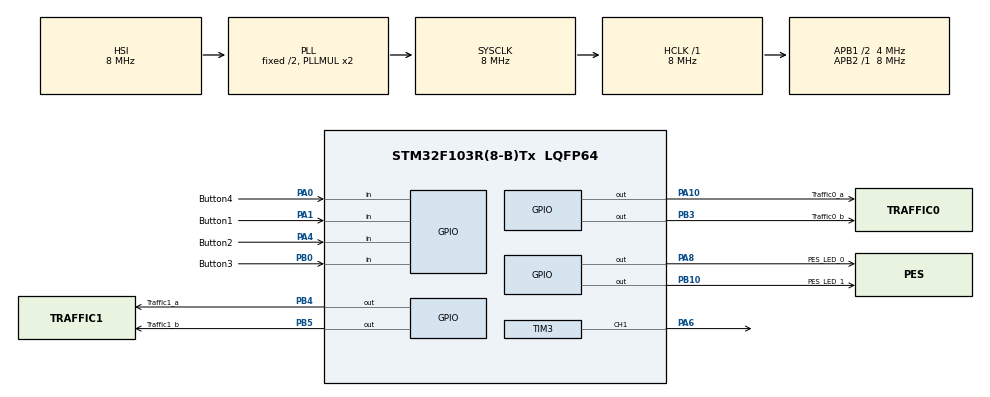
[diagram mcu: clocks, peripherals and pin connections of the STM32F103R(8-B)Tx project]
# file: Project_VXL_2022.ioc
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Mcu.Family=STM32F1
Mcu.Name=STM32F103R(8-B)Tx
Mcu.Package=LQFP64
NVIC.PriorityGroup=NVIC_PRIORITYGROUP_4
NVIC.TIM2_IRQn=true\:0\:0\:false\:false\:true\:true\:true
NVIC.TIM3_IRQn=true\:0\:0\:false\:false\:true\:true\:true
PA0-WKUP.GPIO_Label=Button4
PA0-WKUP.GPIO_PuPd=GPIO_PULLUP
PA0-WKUP.Signal=GPIO_Input
PA1.GPIO_Label=Button1
PA1.GPIO_PuPd=GPIO_PULLUP
PA1.Signal=GPIO_Input
PA10.GPIO_Label=Traffic0_a
PA10.Signal=GPIO_Output
PA13.Mode=Serial_Wire
PA13.Signal=SYS_JTMS-SWDIO
PA14.Mode=Serial_Wire
PA14.Signal=SYS_JTCK-SWCLK
PA4.GPIO_Label=Button2
PA4.GPIO_PuPd=GPIO_PULLUP
PA4.Signal=GPIO_Input
PA6.Signal=S_TIM3_CH1
PA8.GPIO_Label=PES_LED_0
PA8.Signal=GPIO_Output
PB0.GPIO_Label=Button3
PB0.GPIO_PuPd=GPIO_PULLUP
PB0.Signal=GPIO_Input
PB10.GPIO_Label=PES_LED_1
PB10.Signal=GPIO_Output
PB3.GPIO_Label=Traffic0_b
PB3.Signal=GPIO_Output
PB4.GPIO_Label=Traffic1_a
PB4.Signal=GPIO_Output
PB5.GPIO_Label=Traffic1_b
PB5.Signal=GPIO_Output
ProjectManager.HeapSize=0x200
ProjectManager.StackSize=0x400
ProjectManager.TargetToolchain=STM32CubeIDE
RCC.AHBFreq_Value=8000000
RCC.APB1CLKDivider=RCC_HCLK_DIV2
RCC.APB1Freq_Value=4000000
RCC.APB1TimFreq_Value=8000000
RCC.APB2Freq_Value=8000000
RCC.APB2TimFreq_Value=8000000
RCC.HCLKFreq_Value=8000000
RCC.SYSCLKFreq_VALUE=8000000
RCC.SYSCLKSource=RCC_SYSCLKSOURCE_PLLCLK
RCC.USBFreq_Value=8000000
SH.S_TIM3_CH1.0=TIM3_CH1,PWM Generation1 CH1
TIM2.Period=9
TIM2.Prescaler=7999
TIM3.Channel-PWM\ Generation1\ CH1=TIM_CHANNEL_1
TIM3.Period=999
TIM3.Prescaler=63
VP_TIM2_VS_ClockSourceINT.Mode=Internal
VP_TIM3_VS_ClockSourceINT.Mode=Internal
board=custom

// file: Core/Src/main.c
/* USER CODE BEGIN Header */
/**
  ******************************************************************************
  * @file           : main.c
  * @brief          : Main program body
  ******************************************************************************
  * @attention
  *
  * <h2><center>&copy; Copyright (c) 2022 STMicroelectronics.
  * All rights reserved.</center></h2>
  *
  * This software component is licensed by ST under BSD 3-Clause license,
  * the "License"; You may not use this file except in compliance with the
  * License. You may obtain a copy of the License at:
  *                        opensource.org/licenses/BSD-3-Clause
  *
  ******************************************************************************
  */
/* USER CODE END Header */
#include "main.h"
#include "tim.h"
#include "gpio.h"

/* USER CODE BEGIN Includes */
#include "global.h"
/* USER CODE END Includes */

void SystemClock_Config(void);

int main(void)
{

  /* MCU Configuration--------------------------------------------------------*/

  /* Reset of all peripherals, Initializes the Flash interface and the Systick. */
  HAL_Init();

  /* Configure the system clock */
  SystemClock_Config();

  /* Initialize all configured peripherals */
  MX_GPIO_Init();
  MX_TIM2_Init();
  MX_TIM3_Init();
  /* USER CODE BEGIN 2 */
  HAL_TIM_Base_Start_IT(&htim2);
  HAL_TIM_PWM_Start(&htim3, TIM_CHANNEL_1);
  /* USER CODE END 2 */

  /* Infinite loop */
  while (1)
  {

  }
}

void SystemClock_Config(void)
{
  RCC_OscInitTypeDef RCC_OscInitStruct = {0};
  RCC_ClkInitTypeDef RCC_ClkInitStruct = {0};

  /** Initializes the RCC Oscillators according to the specified parameters
  * in the RCC_OscInitTypeDef structure.
  */
  RCC_OscInitStruct.OscillatorType = RCC_OSCILLATORTYPE_HSI;
  RCC_OscInitStruct.HSIState = RCC_HSI_ON;
  RCC_OscInitStruct.HSICalibrationValue = RCC_HSICALIBRATION_DEFAULT;
  RCC_OscInitStruct.PLL.PLLState = RCC_PLL_ON;
  RCC_OscInitStruct.PLL.PLLSource = RCC_PLLSOURCE_HSI_DIV2;
  RCC_OscInitStruct.PLL.PLLMUL = RCC_PLL_MUL2;
  if (HAL_RCC_OscConfig(&RCC_OscInitStruct) != HAL_OK)
  {
    Error_Handler();
  }
  /** Initializes the CPU, AHB and APB buses clocks
  */
  RCC_ClkInitStruct.ClockType = RCC_CLOCKTYPE_HCLK|RCC_CLOCKTYPE_SYSCLK
                              |RCC_CLOCKTYPE_PCLK1|RCC_CLOCKTYPE_PCLK2;
  RCC_ClkInitStruct.SYSCLKSource = RCC_SYSCLKSOURCE_PLLCLK;
  RCC_ClkInitStruct.AHBCLKDivider = RCC_SYSCLK_DIV1;
  RCC_ClkInitStruct.APB1CLKDivider = RCC_HCLK_DIV2;
  RCC_ClkInitStruct.APB2CLKDivider = RCC_HCLK_DIV1;

  if (HAL_RCC_ClockConfig(&RCC_ClkInitStruct, FLASH_LATENCY_0) != HAL_OK)
  {
    Error_Handler();
  }
}

/* USER CODE BEGIN 4 */
void HAL_TIM_PeriodElapsedCallback ( TIM_HandleTypeDef * htim )
{
	fsm_run0();
	fsm_run1();
	//updateManual();
	timerRun(); //every 10ms
	getKeyInput1();
	getKeyInput2();
	getKeyInput3();
	getKeyInput4();
	pes_run();
	buzzer_run();
}
/* USER CODE END 4 */

void Error_Handler(void)
{
  __disable_irq();
  while (1)
  {
  }
}

/************************ (C) COPYRIGHT STMicroelectronics *****END OF FILE****/
